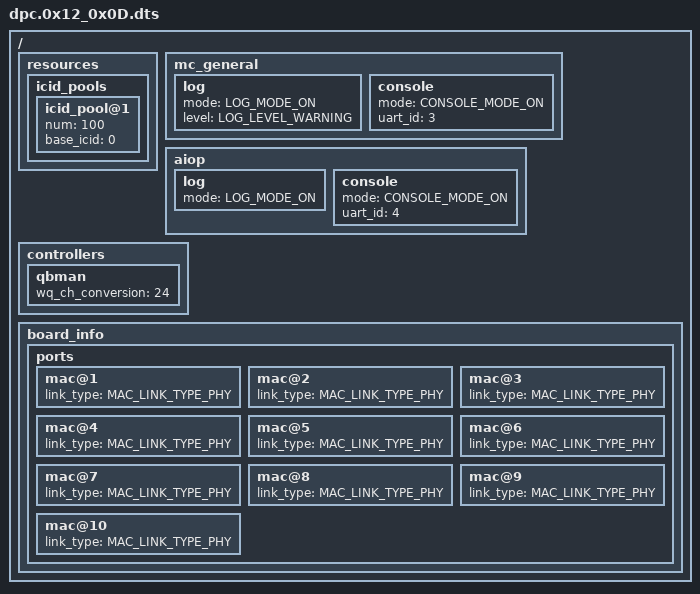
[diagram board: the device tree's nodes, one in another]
/* SPDX-License-Identifier: BSD-3-Clause */
/*
 * Copyright (c) 2019-2022 TQ-Systems GmbH <oss@ew.tq-group.com>
 * D-82229 Seefeld, Germany.
 * Author: Timo Herbrecher, Gregor Herburger
 */

/*
 * This DPC showcases one basic Linux configuration for SerDes 0x12_0x0D.
 */

/dts-v1/;
/ {
	resources {
		icid_pools {
			icid_pool@1 {
				num = <100>;
				base_icid = <0>;
			};
		};
	};
	mc_general {
		/* Configure the DDR log */
		log {
			mode = "LOG_MODE_ON";
			level = "LOG_LEVEL_WARNING";
		};
		/* Configure the UART log */
		/* If CONSOLE_MODE_ON all commands take longer time to execute! */
		console {
			mode = "CONSOLE_MODE_ON";
			uart_id = <3>;
		};
	};
	aiop {
		/* Configure the DDR log */
		log {
			mode = "LOG_MODE_ON";
		};
		/* Configure the UART log */
		/* If CONSOLE_MODE_ON all commands take longer time to execute! */
		console {
			mode = "CONSOLE_MODE_ON";
			uart_id = <4>;
		};
	};
	controllers {
		qbman {
			/* Transform this number of 8-WQ channels into four times
			 * as many 2-WQ channels. This allows the creation of a
			 * larger number of DPCONs.
			 */
			wq_ch_conversion = <24>;
		};
	};
	board_info {
		ports {
			mac@1 {
				link_type = "MAC_LINK_TYPE_PHY";
			};
			mac@2 {
				link_type = "MAC_LINK_TYPE_PHY";
			};
			mac@3 {
				link_type = "MAC_LINK_TYPE_PHY";
			};
			mac@4 {
				link_type = "MAC_LINK_TYPE_PHY";
			};
			mac@5 {
				link_type = "MAC_LINK_TYPE_PHY";
			};
			mac@6 {
				link_type = "MAC_LINK_TYPE_PHY";
			};
			mac@7 {
				link_type = "MAC_LINK_TYPE_PHY";
			};
			mac@8 {
				link_type = "MAC_LINK_TYPE_PHY";
			};
			mac@9 {
				link_type = "MAC_LINK_TYPE_PHY";
			};
			mac@10 {
				link_type = "MAC_LINK_TYPE_PHY";
			};
		};
	};
};
